AUTOSAR XML (schema 00052)
package /apd/AdaptiveApplicationSwComponentTypes
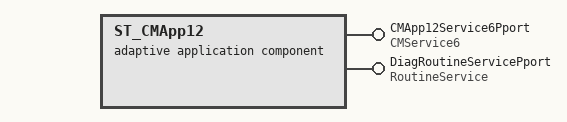
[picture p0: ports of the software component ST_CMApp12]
  adaptive application sw component type ST_CMApp12
    provide port CMApp12Service6Pport: provided-interface=CMService6
    provide port DiagRoutineServicePport: provided-interface=RoutineService
package /apd/Executables
  executable ST_CMApp12: category=APPLICATION_LEVEL, minimum-timer-granularity=1000.0
    root sw component prototype ST_CMApp12Root: application-type=ST_CMApp12
